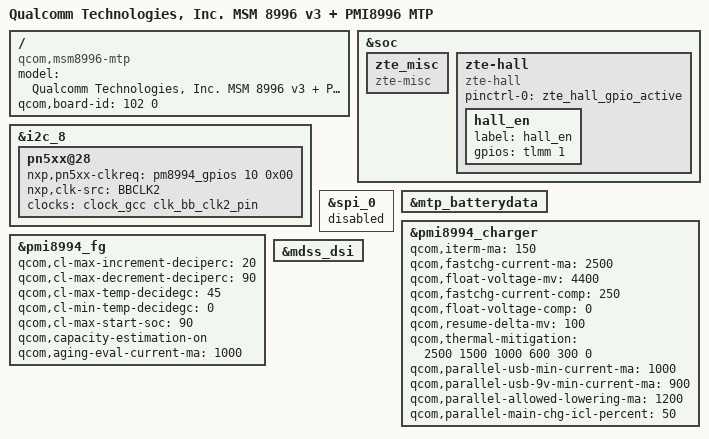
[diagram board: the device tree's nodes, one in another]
/* TWRP-only Fujisan DTB: retain the dual-DSI topology, but expose panel A
 * through its native framebuffer rather than the Android composite display. */
/dts-v1/;

#include "msm8996pro-v1.1.dtsi"
#include "msm-pmi8996.dtsi"
#include "msm8996-mtp-fujisan.dtsi"
#include "zte-msm8996-fujisan-pinctrl.dtsi"
#include "zte-camera-sensor-mtp-fujisan.dtsi"
#include "zte-msm8996pro-v1.1-pmi8996-fujisan.dtsi"

/ {
	model = "Qualcomm Technologies, Inc. MSM 8996 v3 + PMI8996 MTP";
	compatible = "qcom,msm8996-mtp", "qcom,msm8996", "qcom,mtp";
	qcom,board-id = <102 0>;
};

&soc {
	zte_misc {
		compatible = "zte-misc";
	};
	zte-hall {
		compatible = "zte-hall";
		pinctrl-names = "zte_hall_gpio_active";
		pinctrl-0 = <&zte_hall_gpio_active>;
		hall_en {
			label = "hall_en";
			gpios = <&tlmm 1 0x0>;
		};
	};
};

&i2c_8 {
	pn5xx@28 {
		nxp,pn5xx-clkreq = <&pm8994_gpios 10 0x00>;
		nxp,clk-src = "BBCLK2";
		clocks = <&clock_gcc clk_bb_clk2_pin>;
		clock-names = "bb_clk2";
	};
};

&spi_0 {
	status = "disabled";
};

&mtp_batterydata {
	#include "zte_p996a20_3180mAh.dtsi"
};

&pmi8994_charger {
	qcom,iterm-ma = <150>;
	qcom,fastchg-current-ma = <2500>;
	qcom,float-voltage-mv = <4400>;
	qcom,fastchg-current-comp = <250>;
	qcom,float-voltage-comp = <0>;
	qcom,resume-delta-mv = <100>;
	qcom,thermal-mitigation = <2500 1500 1000 600 300 0>;
	qcom,parallel-usb-min-current-ma = <1000>;
	qcom,parallel-usb-9v-min-current-ma = <900>;
	qcom,parallel-allowed-lowering-ma = <1200>;
	qcom,parallel-main-chg-icl-percent = <50>;
};

&pmi8994_fg {
	qcom,cl-max-increment-deciperc = <20>;
	qcom,cl-max-decrement-deciperc = <90>;
	qcom,cl-max-temp-decidegc = <45>;
	qcom,cl-min-temp-decidegc = <0>;
	qcom,cl-max-start-soc = <90>;
	qcom,capacity-estimation-on;
	qcom,aging-eval-current-ma = <1000>;
};

&mdss_dsi {
	/delete-property/ zte,fujisan-composite-stage1;
};
